VERSION ""

NS_ :

BS_:

BU_:

BO_ 2583177470 WPRWSH_RainData: 1 Vector__XXX
 SG_ RainIntensity : 0|3@1+ (1,0) [0|7] "" Vector__XXX

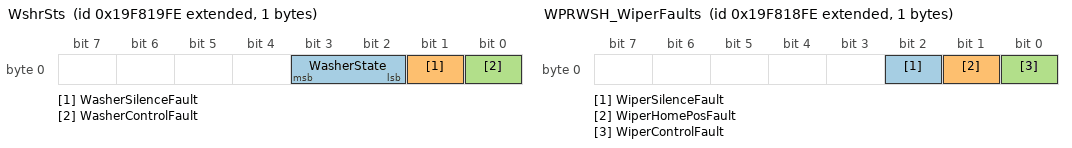
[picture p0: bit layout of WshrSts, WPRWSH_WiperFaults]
BO_ 2583173630 WshrSts: 1 Vector__XXX
 SG_ WasherState : 2|2@1+ (1,0) [0|3] "" Vector__XXX
 SG_ WasherSilenceFault : 1|1@1+ (1,0) [0|1] "" Vector__XXX
 SG_ WasherControlFault : 0|1@1+ (1,0) [0|1] "" Vector__XXX

BO_ 2583173374 WPRWSH_WiperFaults: 1 Vector__XXX
 SG_ WiperSilenceFault : 2|1@1+ (1,0) [0|1] "" Vector__XXX
 SG_ WiperHomePosFault : 1|1@1+ (1,0) [0|1] "" Vector__XXX
 SG_ WiperControlFault : 0|1@1+ (1,0) [0|1] "" Vector__XXX

BO_ 2583174654 WPRWSH_WiperFeedback: 1 Vector__XXX
 SG_ WiperHomePosition : 0|1@1+ (1,0) [0|1] "" Vector__XXX
 SG_ WiperState : 1|3@1+ (1,0) [0|7] "" Vector__XXX

BO_ 2583173886 WPRWSH_UserRequest: 1 Vector__XXX
 SG_ WipeRequest : 2|3@1+ (1,0) [0|7] "" Vector__XXX
 SG_ WashRequest : 0|2@1+ (1,0) [0|3] "" Vector__XXX

BO_ 2583175166 WPRWSH_WiperArbReq: 1 Vector__XXX
 SG_ WipeArbRequest : 0|3@1+ (1,0) [0|7] "" Vector__XXX

CM_ "$File: //depot/auto/dbc/Software_Modules/Windshield_Wash_Wipe/WPRWSH/0.0.8.0/WPRWSH.dbc $
$Change: 215986 $
$DateTime: 2024/08/21 10:12:55 $
$Revision: #1 $";
CM_ BO_ 2583177470 "Rain data from the Rain Sensor Driver.";
CM_ SG_ 2583177470 RainIntensity "Rain intensity logical interpretation.";
CM_ BO_ 2583173630 "Washer faults & status from the Washer Controller.";
CM_ SG_ 2583173630 WasherState "Current state of the Washer Driver.";
CM_ SG_ 2583173630 WasherSilenceFault "Indicates if Washer Driver feedback is not on CAN network.";
CM_ SG_ 2583173630 WasherControlFault "Indicates if Washer failed to execute command from the Washer Controller.";
CM_ BO_ 2583173374 "Wiper faults detected by the Wiper Controller.";
CM_ SG_ 2583173374 WiperSilenceFault "Indicates if Wiper Driver feedback is not on CAN network.";
CM_ SG_ 2583173374 WiperHomePosFault "Indicates if Wiper failed ''home position''.";
CM_ SG_ 2583173374 WiperControlFault "Indicates if Wiper failed to execute command from the Wiper Controller.";
CM_ BO_ 2583174654 "Feedback from the Wiper Driver.";
CM_ SG_ 2583174654 WiperHomePosition "Indicates if Wiper is in ''home position''.";
CM_ SG_ 2583174654 WiperState "Current state of the Wiper Driver.";
CM_ BO_ 2583173886 "Requests from the HMI to the Washer and Wiper controllers.";
CM_ SG_ 2583173886 WipeRequest "Request from the HMI to the Wiper Controller.";
CM_ SG_ 2583173886 WashRequest "Request from the HMI to the Washer Controller.";
CM_ BO_ 2583175166 "Message with wiper status";
CM_ SG_ 2583175166 WipeArbRequest "Represent selected wiper status for HMI";
BA_DEF_  "DBName" STRING ;
BA_DEF_ SG_  "SigType" ENUM  "Default","Range","RangeSigned","ASCII","Discrete","Control","ReferencePGN","DTC","StringDelimiter","StringLength","StringLengthControl","MessageCounter","MessageChecksum";
BA_DEF_ SG_  "GenSigStartValue" INT 0 2147483647;
BA_DEF_ BO_  "GenMsgDelayTime" INT 0 1000;
BA_DEF_ BO_  "GenMsgRequestable" INT 0 1;
BA_DEF_ BO_  "GenMsgSendType" ENUM  "cyclic","NotUsed","NotUsed","NotUsed","NotUsed","NotUsed","NotUsed","IfActive","noMsgSendType";
BA_DEF_ BO_  "VFrameFormat" ENUM  "StandardCAN","ExtendedCAN","reserved","J1939PG","reserved","reserved","reserved","reserved","reserved","reserved","reserved","reserved","reserved","reserved","StandardCAN_FD","ExtendedCAN_FD";
BA_DEF_ BO_  "GenMsgCycleTime" INT 0 3600000;
BA_DEF_ BO_  "SendOnChange" ENUM  "No","Yes";
BA_DEF_ BU_  "NmStationAddress" INT 0 255;
BA_DEF_  "DatabaseVersion" STRING ;
BA_DEF_  "BusType" STRING ;
BA_DEF_  "ProtocolType" STRING ;
BA_DEF_ BO_  "Producer" STRING ;
BA_DEF_DEF_  "DBName" "";
BA_DEF_DEF_  "SigType" "Default";
BA_DEF_DEF_  "GenSigStartValue" 0;
BA_DEF_DEF_  "GenMsgDelayTime" 0;
BA_DEF_DEF_  "GenMsgRequestable" 1;
BA_DEF_DEF_  "GenMsgSendType" "noMsgSendType";
BA_DEF_DEF_  "VFrameFormat" "J1939PG";
BA_DEF_DEF_  "GenMsgCycleTime" 0;
BA_DEF_DEF_  "SendOnChange" "No";
BA_DEF_DEF_  "NmStationAddress" 254;
BA_DEF_DEF_  "DatabaseVersion" "";
BA_DEF_DEF_  "BusType" "";
BA_DEF_DEF_  "ProtocolType" "";
BA_DEF_DEF_  "Producer" "";
BA_ "ProtocolType" "J1939";
BA_ "BusType" "CAN";
BA_ "DatabaseVersion" "8.5";
BA_ "DBName" "WPRWSH";
BA_ "Producer" BO_ 2583177470 "WAWS";
BA_ "GenMsgDelayTime" BO_ 2583177470 100;
BA_ "GenMsgCycleTime" BO_ 2583177470 1000;
BA_ "GenMsgSendType" BO_ 2583177470 0;
BA_ "SendOnChange" BO_ 2583177470 1;
BA_ "Producer" BO_ 2583173630 "WAWS";
BA_ "GenMsgCycleTime" BO_ 2583173630 1000;
BA_ "GenMsgSendType" BO_ 2583173630 0;
BA_ "SendOnChange" BO_ 2583173630 1;
BA_ "GenMsgDelayTime" BO_ 2583173630 100;
BA_ "Producer" BO_ 2583173374 "WAWS";
BA_ "GenMsgDelayTime" BO_ 2583173374 100;
BA_ "GenMsgSendType" BO_ 2583173374 0;
BA_ "SendOnChange" BO_ 2583173374 1;
BA_ "GenMsgCycleTime" BO_ 2583173374 1000;
BA_ "Producer" BO_ 2583174654 "WAWS";
BA_ "GenMsgSendType" BO_ 2583174654 0;
BA_ "SendOnChange" BO_ 2583174654 1;
BA_ "GenMsgCycleTime" BO_ 2583174654 1000;
BA_ "GenMsgDelayTime" BO_ 2583174654 100;
BA_ "Producer" BO_ 2583173886 "WAWS";
BA_ "GenMsgDelayTime" BO_ 2583173886 100;
BA_ "GenMsgSendType" BO_ 2583173886 0;
BA_ "SendOnChange" BO_ 2583173886 1;
BA_ "GenMsgCycleTime" BO_ 2583173886 1000;
BA_ "Producer" BO_ 2583175166 "WAWS";
BA_ "GenMsgDelayTime" BO_ 2583175166 100;
BA_ "GenMsgSendType" BO_ 2583175166 0;
BA_ "SendOnChange" BO_ 2583175166 1;
BA_ "GenMsgCycleTime" BO_ 2583175166 1000;
VAL_ 2583177470 RainIntensity 7 "RAIN_NA" 6 "RAIN_Error" 5 "RAIN_Reserved2" 4 "RAIN_Reserved1" 3 "RAIN_High" 2 "RAIN_Medium" 1 "RAIN_Low" 0 "RAIN_Off" ;
VAL_ 2583173630 WasherState 3 "WSH_NA" 2 "WSH_Error" 1 "WSH_On" 0 "WSH_Off" ;
VAL_ 2583174654 WiperState 7 "WPR_NA" 6 "WPR_Error" 5 "WPR_Reserved3" 4 "WPR_Reserved2" 3 "WPR_Reserved1" 2 "WPR_HighSpeed" 1 "WPR_LowSpeed" 0 "WPR_Off" ;
VAL_ 2583173886 WipeRequest 7 "WPR_NA" 6 "WPR_Reserved" 5 "WPR_Auto" 4 "WPR_HighSpeed" 3 "WPR_LowSpeed" 2 "WPR_Intermittent" 1 "WPR_SingleStroke" 0 "WPR_TurnOff" ;
VAL_ 2583173886 WashRequest 3 "NA" 2 "Error" 1 "WSH_TurnOn" 0 "WSH_TurnOff" ;
VAL_ 2583175166 WipeArbRequest 7 "WPR_NA" 6 "WPR_Reserved" 5 "WPR_Auto" 4 "WPR_HighSpeed" 3 "WPR_LowSpeed" 2 "WPR_Intermittent" 1 "WPR_SingleStroke" 0 "WPR_TurnOff" ;
